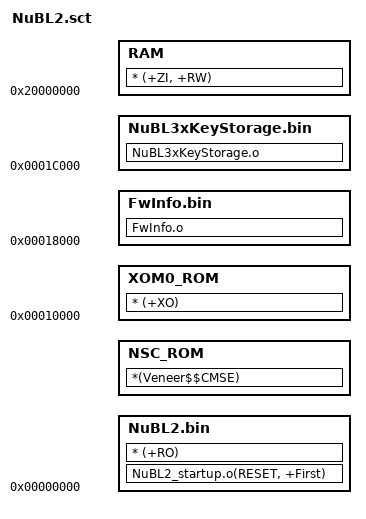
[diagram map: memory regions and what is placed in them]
NUBL2 0x0
{
    NuBL2.bin +0
    {
        NuBL2_startup.o(RESET, +First)
        * (+RO)
    }
    
    NSC_ROM +0
    {
        *(Veneer$$CMSE)
    }
    
    RAM 0x20000000
    {
        * (+ZI, +RW)
    }
}

XOM0 0x10000    ; located in 64K
{
    XOM0_ROM +0
    {
        * (+XO)
    }    
}

NUBL2_INFO 0x18000  ; located in 96K
{
    FwInfo.bin +0
    {
        FwInfo.o
    }
}

NUBL3x_KEYSTOGAGE 0x1C000   ; located in 112K
{
    NuBL3xKeyStorage.bin +0
    {
        NuBL3xKeyStorage.o
    }
}
